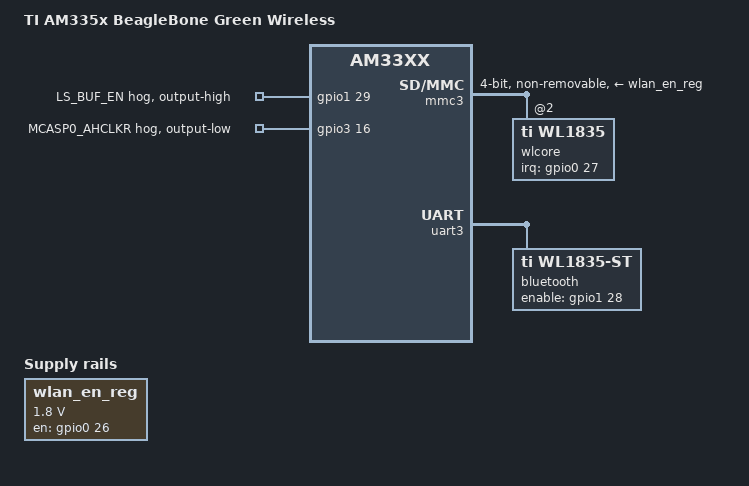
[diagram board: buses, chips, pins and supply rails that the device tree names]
/dts-v1/;
#include "am33xx.dtsi"
#include "am335x-bone-common.dtsi"
#include "am335x-bonegreen-common.dtsi"
#include <dt-bindings/interrupt-controller/irq.h>
/ {
	model = "TI AM335x BeagleBone Green Wireless";
	compatible = "ti,am335x-bone-green-wireless", "ti,am335x-bone-green", "ti,am335x-bone-black", "ti,am335x-bone", "ti,am33xx";
	wlan_en_reg: fixedregulator@2 {
		compatible = "regulator-fixed";
		regulator-name = "wlan-en-regulator";
		regulator-min-microvolt = <1800000>;
		regulator-max-microvolt = <1800000>;
		startup-delay-us = <70000>;
		gpio = <&gpio0 26 0>;
		enable-active-high;
	};
};
&am33xx_pinmux {
	bt_pins: bt-pins {
		pinctrl-single,pins = <
			AM33XX_PADCONF(AM335X_PIN_GPMC_BEN1, PIN_OUTPUT_PULLUP, MUX_MODE7)	 
		>;
	};
	mmc3_pins: mmc3-pins {
		pinctrl-single,pins = <
			AM33XX_PADCONF(AM335X_PIN_GPMC_AD12, PIN_INPUT_PULLUP, MUX_MODE3)	 
			AM33XX_PADCONF(AM335X_PIN_GPMC_AD13, PIN_INPUT_PULLUP, MUX_MODE3)	 
			AM33XX_PADCONF(AM335X_PIN_GPMC_AD14, PIN_INPUT_PULLUP, MUX_MODE3)	 
			AM33XX_PADCONF(AM335X_PIN_GPMC_AD15, PIN_INPUT_PULLUP, MUX_MODE3)	 
			AM33XX_PADCONF(AM335X_PIN_GPMC_CSN3, PIN_INPUT_PULLUP, MUX_MODE3)	 
			AM33XX_PADCONF(AM335X_PIN_GPMC_CLK, PIN_INPUT_PULLUP, MUX_MODE3)	 
		>;
	};
	uart3_pins: uart3-pins {
		pinctrl-single,pins = <
			AM33XX_PADCONF(AM335X_PIN_MII1_RXD3, PIN_INPUT_PULLUP, MUX_MODE1)	 
			AM33XX_PADCONF(AM335X_PIN_MII1_RXD2, PIN_OUTPUT_PULLDOWN, MUX_MODE1)	 
			AM33XX_PADCONF(AM335X_PIN_MDIO, PIN_INPUT, MUX_MODE3)		 
			AM33XX_PADCONF(AM335X_PIN_MDC, PIN_OUTPUT_PULLDOWN, MUX_MODE3)	 
		>;
	};
	wl18xx_pins: wl18xx-pins {
		pinctrl-single,pins = <
			AM33XX_PADCONF(AM335X_PIN_GPMC_AD10, PIN_OUTPUT_PULLDOWN, MUX_MODE7)	 
			AM33XX_PADCONF(AM335X_PIN_GPMC_AD11, PIN_INPUT_PULLDOWN, MUX_MODE7)	 
			AM33XX_PADCONF(AM335X_PIN_GPMC_CSN0, PIN_OUTPUT_PULLUP, MUX_MODE7)	 
		>;
	};
};
&mac_sw {
	status = "disabled";
};
&mmc3 {
	dmas = <&edma_xbar 12 0 1
		&edma_xbar 13 0 2>;
	dma-names = "tx", "rx";
	status = "okay";
	vmmc-supply = <&wlan_en_reg>;
	bus-width = <4>;
	non-removable;
	cap-power-off-card;
	keep-power-in-suspend;
	pinctrl-names = "default";
	pinctrl-0 = <&mmc3_pins &wl18xx_pins>;
	#address-cells = <1>;
	#size-cells = <0>;
	wlcore: wlcore@2 {
		compatible = "ti,wl1835";
		reg = <2>;
		interrupt-parent = <&gpio0>;
		interrupts = <27 IRQ_TYPE_EDGE_RISING>;
	};
};
&uart3 {
	pinctrl-names = "default";
	pinctrl-0 = <&uart3_pins &bt_pins>;
	status = "okay";
	bluetooth {
		compatible = "ti,wl1835-st";
		enable-gpios = <&gpio1 28 GPIO_ACTIVE_HIGH>;
	};
};
&gpio1 {
	ls-buf-en-hog {
		gpio-hog;
		gpios = <29 GPIO_ACTIVE_HIGH>;
		output-high;
		line-name = "LS_BUF_EN";
	};
};
&gpio3 {
	bt-aud-in-hog {
		gpio-hog;
		gpios = <16 GPIO_ACTIVE_HIGH>;
		output-low;
		line-name = "MCASP0_AHCLKR";
	};
};
